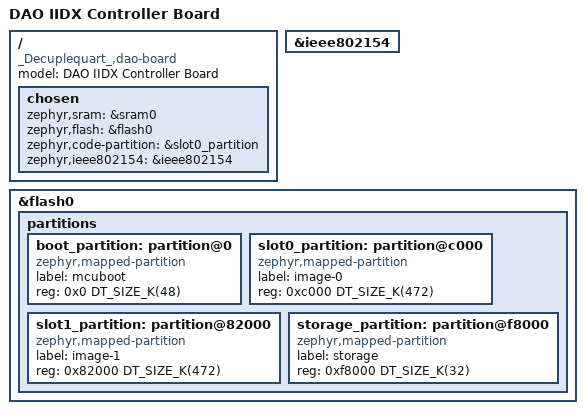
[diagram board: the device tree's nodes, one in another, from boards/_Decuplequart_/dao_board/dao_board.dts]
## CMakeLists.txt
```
#
# Copyright (c) 2025 Nordic Semiconductor ASA
#
# SPDX-License-Identifier: LicenseRef-Nordic-5-Clause
#

cmake_minimum_required(VERSION 3.20.0)

find_package(Zephyr REQUIRED HINTS $ENV{ZEPHYR_BASE})
project(dao_board_firmware)

target_sources(app PRIVATE
    src/main.c
)
```

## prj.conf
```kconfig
CONFIG_GPIO=y
CONFIG_CONSOLE=y
CONFIG_PRINTK=y
CONFIG_SERIAL=y
```

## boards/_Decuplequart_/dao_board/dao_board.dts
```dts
/dts-v1/;

#include <nordic/nrf52840_qiaa.dtsi>
#include "dao_board-pinctrl.dtsi"

/ {
	model = "DAO IIDX Controller Board";
	compatible = "_Decuplequart_,dao-board";

	chosen {
		zephyr,sram = &sram0;
		zephyr,flash = &flash0;
		zephyr,code-partition = &slot0_partition;
		zephyr,ieee802154 = &ieee802154;
	};
};

&ieee802154 {
	status = "okay";
};

&flash0 {
	partitions {
		#address-cells = <1>;
		#size-cells = <1>;
		ranges;

		boot_partition: partition@0 {
			compatible = "zephyr,mapped-partition";
			label = "mcuboot";
			reg = <0x0 DT_SIZE_K(48)>;
		};

		slot0_partition: partition@c000 {
			compatible = "zephyr,mapped-partition";
			label = "image-0";
			reg = <0xc000 DT_SIZE_K(472)>;
		};

		slot1_partition: partition@82000 {
			compatible = "zephyr,mapped-partition";
			label = "image-1";
			reg = <0x82000 DT_SIZE_K(472)>;
		};

		storage_partition: partition@f8000 {
			compatible = "zephyr,mapped-partition";
			label = "storage";
			reg = <0xf8000 DT_SIZE_K(32)>;
		};
	};
};
```

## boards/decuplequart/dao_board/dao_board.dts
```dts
/dts-v1/;

#include <nordic/nrf52840_qiaa.dtsi>
#include "dao_board-pinctrl.dtsi"

/ {
	model = "DAO IIDX Controller Board";
	compatible = "decuplequart,dao-board";

	chosen {
		zephyr,sram = &sram0;
		zephyr,flash = &flash0;
		zephyr,code-partition = &slot0_partition;
		zephyr,ieee802154 = &ieee802154;
	};
};

&ieee802154 {
	status = "okay";
};

&flash0 {
	partitions {
		#address-cells = <1>;
		#size-cells = <1>;
		ranges;

		boot_partition: partition@0 {
			compatible = "zephyr,mapped-partition";
			label = "mcuboot";
			reg = <0x0 DT_SIZE_K(48)>;
		};

		slot0_partition: partition@c000 {
			compatible = "zephyr,mapped-partition";
			label = "image-0";
			reg = <0xc000 DT_SIZE_K(472)>;
		};

		slot1_partition: partition@82000 {
			compatible = "zephyr,mapped-partition";
			label = "image-1";
			reg = <0x82000 DT_SIZE_K(472)>;
		};

		storage_partition: partition@f8000 {
			compatible = "zephyr,mapped-partition";
			label = "storage";
			reg = <0xf8000 DT_SIZE_K(32)>;
		};
	};
};
```

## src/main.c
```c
#include <zephyr/kernel.h>
#include <zephyr/sys/printk.h>

int main(void)
{
    printk("DAO board firmware started\n");

    while (1) {
        printk("alive\n");
        k_sleep(K_SECONDS(1));
    }

    return 0;
}
```
